# S32M24x register map
Vendor: NXP Semiconductors; File version: 1.3
CPU: CM4 r0p1, little endian, MPU, FPU, VTOR, 4 interrupt priority bits
Registers are 32-bit, read-write, reset 0x0 unless marked. A register's access mark holds for its fields unless they carry their own. Offsets are from the block's base; [hi:lo] are bit positions; {n}, {i} and the like mark numbered series; 'fields as' and 'values as' point back to an identical list.

## AEC_AE — AEC
Base 0x00000000
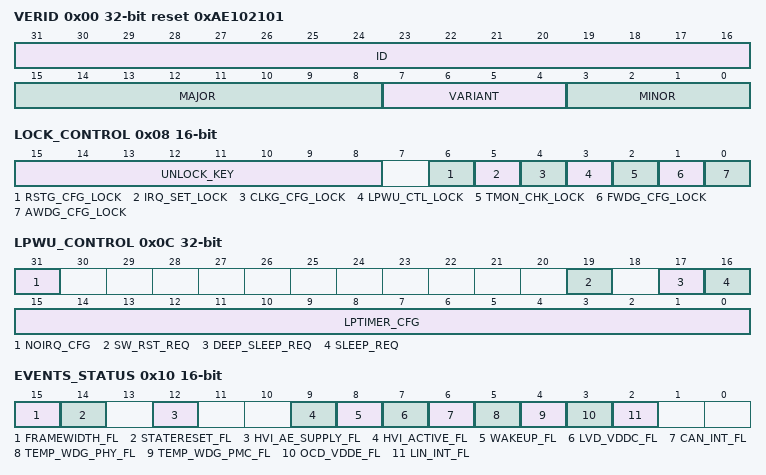
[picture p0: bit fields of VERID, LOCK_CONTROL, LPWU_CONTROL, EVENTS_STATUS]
0x00 VERID ro reset 0xAE102101 — AEC Version ID
  [31:16] ID — Unique Identifier
  [15:8] MAJOR — Major Revision
  [7:4] VARIANT
    0bxxx1=NoCXPI (CXPI is disabled)
  [3:0] MINOR — Minor Revision
0x08 LOCK_CONTROL 16-bit
  [15:8] UNLOCK_KEY
  [6] RSTG_CFG_LOCK — Lock Write Access to RSTGEN_CFG
  [5] IRQ_SET_LOCK — Lock Write Access to IRQ_SET
  [4] CLKG_CFG_LOCK — Lock Write Access to CLKGEN_CFG
  [3] LPWU_CTL_LOCK — Lock Write Access to LPWU_CONTROL
  [2] TMON_CHK_LOCK — Temperature Sensor Check Lock
  [1] FWDG_CFG_LOCK — Lock Write Access to Configuration of the FAULT Watchdog
  [0] AWDG_CFG_LOCK — Lock Write Access to Registers of the Alive Watchdog
0x0C LPWU_CONTROL — Power Mode Control
  [31] NOIRQ_CFG — No IRQ After Reset
  [19] SW_RST_REQ — Software Reset Request
  [17] DEEP_SLEEP_REQ — Deep Sleep Request
  [16] SLEEP_REQ — Sleep Request
  [15:0] LPTIMER_CFG — LP Timer Configuration
0x10 EVENTS_STATUS 16-bit — Event Notifications Status
  [15] FRAMEWIDTH_FL write-1-clears — SPI Framewidth Notification Flag
  [14] STATERESET_FL write-1-clears — State Machine Reset Notification Flag
  [12] HVI_AE_SUPPLY_FL ro — HVI1 Notification Flag
  [9] HVI_ACTIVE_FL ro — HVI0 Notification Flag
  [8] WAKEUP_FL write-1-clears — Wake-up Notification Flag
  [7] LVD_VDDC_FL ro — LVD Vddc Notification Flag
  [6] CAN_INT_FL ro — CANPHY Notification Flag
  [5] TEMP_WDG_PHY_FL ro — Temperature Monitor PHY Notification Flag
  [4] TEMP_WDG_PMC_FL ro — Temperature Monitor PMC Notification Flag
  [3] OCD_VDDE_FL write-1-clears — Over Current Detector Notification Flag
  [2] LIN_INT_FL ro — LINPHY Notification Flag
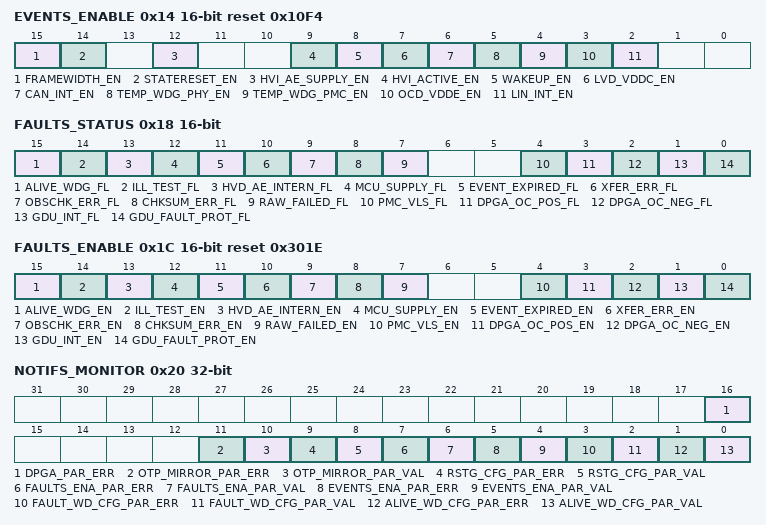
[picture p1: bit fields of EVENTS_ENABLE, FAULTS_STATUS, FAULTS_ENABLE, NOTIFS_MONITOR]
0x14 EVENTS_ENABLE 16-bit reset 0x10F4 — Event Notifications Enable
  [15] FRAMEWIDTH_EN — SPI Framewidth Notification Enable
  [14] STATERESET_EN — State Machine Reset Notification Enable
  [12] HVI_AE_SUPPLY_EN ro — HVM1 Notification Enable
  [9] HVI_ACTIVE_EN — HVM0 Notification Enable
  [8] WAKEUP_EN — Wake Up Notification Enable
  [7] LVD_VDDC_EN ro — LVD VDDC Notification Enable
  [6] CAN_INT_EN ro — CANPHY Notification Enable
  [5] TEMP_WDG_PHY_EN ro — Temperature Sensor PHY Notification Enable
  [4] TEMP_WDG_PMC_EN ro — Temperature Sensor PMC Notification Enable
  [3] OCD_VDDE_EN — Over Current Detector Notification Enable
  [2] LIN_INT_EN ro — LINPHY Notification Enable
0x18 FAULTS_STATUS 16-bit — Fault Notifications Status
  [15] ALIVE_WDG_FL write-1-clears — Alive Watchdog Flag
  [14] ILL_TEST_FL write-1-clears — Illegal Test Notification Flag
  [13] HVD_AE_INTERN_FL ro — HVD Notification Flag
  [12] MCU_SUPPLY_FL ro — MCU Supply Notification Flag
  [11] EVENT_EXPIRED_FL write-1-clears — Event Expired Notification Flag
  [10] XFER_ERR_FL write-1-clears — Transfer Error Notification Flag
  [9] OBSCHK_ERR_FL write-1-clears — OBSCHK Error Notification Flag
  [8] CHKSUM_ERR_FL write-1-clears — Checksum Error Notification Flag
  [7] RAW_FAILED_FL write-1-clears — RAW Failed Notification Flag
  [4] PMC_VLS_FL ro — PMC VLS Notification Flag
  [3] DPGA_OC_POS_FL ro — DPGA OC POS Notification Flag
  [2] DPGA_OC_NEG_FL ro — DPGA OC NEG Notification Flag
  [1] GDU_INT_FL ro — GDU Notification Flag
  [0] GDU_FAULT_PROT_FL ro — GDU Fault Protection Notification Flag
0x1C FAULTS_ENABLE 16-bit reset 0x301E — Fault Notifications Enable
  [15] ALIVE_WDG_EN — Alive Watchdog Notification Enable
  [14] ILL_TEST_EN — Illegal Test Notification Enable
  [13] HVD_AE_INTERN_EN ro — HVD Internal Notification Enable
  [12] MCU_SUPPLY_EN ro — MCU Supply Notification Enable
  [11] EVENT_EXPIRED_EN — Event Expired Notification Enable
  [10] XFER_ERR_EN — Transfer Error Notification Enable
  [9] OBSCHK_ERR_EN — OBSCHK Error Notification Enable
  [8] CHKSUM_ERR_EN — Checksum Error Notification Enable
  [7] RAW_FAILED_EN — RAW Failed Notification Enable
  [4] PMC_VLS_EN ro — PMC VLS Notification Enable
  [3] DPGA_OC_POS_EN ro — DPGA OC POS Notification Enable
  [2] DPGA_OC_NEG_EN ro — DPGA OC NEG Notification Enable
  [1] GDU_INT_EN ro — GDU Notification Enable
  [0] GDU_FAULT_PROT_EN — GDU Fault Protection Notification Enable
0x20 NOTIFS_MONITOR — Monitoring of Notifications
  [16] DPGA_PAR_ERR write-1-clears — Current Parity Value Error
  [11] OTP_MIRROR_PAR_ERR write-1-clears — Current Parity Value Error
  [10] OTP_MIRROR_PAR_VAL — Parity Value Of Mirror Registers After Completion Of Otp Boot
  [9] RSTG_CFG_PAR_ERR write-1-clears — Current Parity Value Error
  [8] RSTG_CFG_PAR_VAL — Current Parity Value
  [7] FAULTS_ENA_PAR_ERR write-1-clears — Current Parity Value Error
  [6] FAULTS_ENA_PAR_VAL — Current Parity Value
  [5] EVENTS_ENA_PAR_ERR write-1-clears — Current Parity Value Error
  [4] EVENTS_ENA_PAR_VAL — Current Parity Value
  [3] FAULT_WD_CFG_PAR_ERR write-1-clears — Current Parity Value Error
  [2] FAULT_WD_CFG_PAR_VAL — Current Parity Value
  [1] ALIVE_WD_CFG_PAR_ERR write-1-clears — Current Parity Value Error
  [0] ALIVE_WD_CFG_PAR_VAL — Current Parity Value
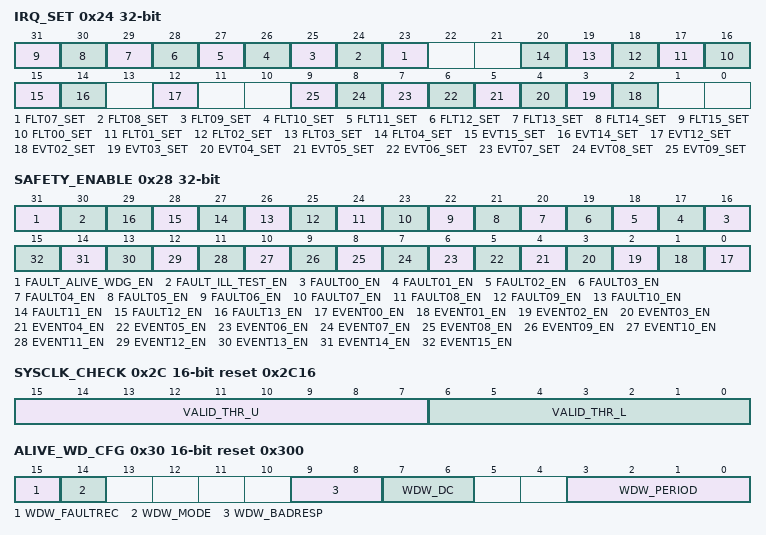
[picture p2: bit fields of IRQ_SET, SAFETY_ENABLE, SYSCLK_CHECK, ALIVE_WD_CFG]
0x24 IRQ_SET — Set Status Bits
  [n+16] FLT{n:02}_SET (n=7..15) — Forces Flag Corresponding To Fault {n}
  [n+16] FLT{n:02}_SET (n=0..4) — Forces Flag Corresponding To Fault {n}
  [15] EVT15_SET — Forces Flag Corresponding to Event 15
  [14] EVT14_SET — Forces Flag Corresponding to Event 14
  [12] EVT12_SET — Forces Flag Corresponding To Event 12
  [n] EVT{n:02}_SET (n=2..9) — Forces Flag Corresponding To Event {n}
0x28 SAFETY_ENABLE
  [31] FAULT_ALIVE_WDG_EN — Safe State Enable For FAULT ALIVE_WDG
  [30] FAULT_ILL_TEST_EN — Safe State Enable For FAULT ILL_TEST
  [n+16] FAULT{n:02}_EN ro (n=0..13) — Not Used
  [n] EVENT{n:02}_EN ro (n=0..15) — Not Used
0x2C SYSCLK_CHECK 16-bit reset 0x2C16 — System Clock Check
  [15:7] VALID_THR_U — Valid System Clock Threshold Range, Upper Boundary
  [6:0] VALID_THR_L — Valid System Clock Threshold Range, Lower Boundary
0x30 ALIVE_WD_CFG 16-bit reset 0x300 — Alive Watchdog Configuration
  [15] WDW_FAULTREC — Fault Response Configuration
    0=Unserviced watchdog triggers a fault notification (ALIVE_WDG); 1=Unserviced watchdog triggers a device reset
  [14] WDW_MODE — Watchdog Mode
    0=Simple mode. Expected response is token; 1=Challenge mode. Expected response is given by a LFSR
  [9:8] WDW_BADRESP — Max Number Of Bad Responses. Access Are Locked
    0=First incorrect response token triggers a fault event; 1=One incorrect response token permitted before triggering a fault event; 2=Two incorrect response token permitted before triggering a fault event; 3=Three incorrect response token permitted before triggering a fault event
  [7:6] WDW_DC — Window duty cycle
    0=d0 (0% Closed (feature disabled)); 1=d1 (First 31.25% closed (exact ratio: 1/2-1/4+1/16)); 2=d2 (First 50% closed); 3=d3 (First 68.75% closed (exact ratio: 1/2+1/4-1/16))
  [3:0] WDW_PERIOD — Watchdog Window Duration. Access Are Locked.
    0=d0 (Disabled); {v}=d{v} ({v}*2*512 us) (v=1..4); 5=d5 (6*2*512 us); 6=d6 (8*2*512 us); 7=d7 (23*512 us); 8=d8 (31*512 us); 9=d9 (47*512 us); 10=d10 (62*512 us); 11=d11 (125*512 us); 12=d12 (250*512 us); 13=d13 (500*512 us); 14=d14 (1000*512 us); 15=d15 (2000*512 us)
0x34 ALIVE_WD_TOKEN 16-bit reset 0x5AB2 — Alive Watchdog Reference Value
  [15:0] WD_TOKEN — Token
0x38 ALIVE_WD_ANSWER 16-bit — Alive Watchdog Answer
  [15:0] WD_ANSWER — Answer
0x3C FAULT_WD_CFG 16-bit — Fault Watchdog Configuration
  [11:0] TIME_OUT_CFG — Window Period
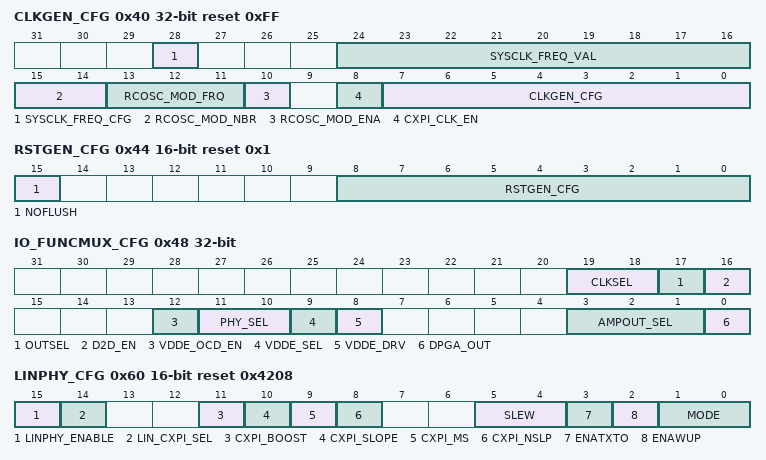
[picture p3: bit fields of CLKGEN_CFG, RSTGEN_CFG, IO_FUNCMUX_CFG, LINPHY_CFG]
0x40 CLKGEN_CFG reset 0xFF — Clock Generator Configuration
  [28] SYSCLK_FREQ_CFG — System Clock Frequency Estimator Configuration
  [24:16] SYSCLK_FREQ_VAL ro — System Clock Frequency Estimator Result
  [15:14] RCOSC_MOD_NBR — RCOSC: number of modulation used for spreading frequency.
    0=The modulation of the RCosc change between 2 frequencies; 1=The modulation of the RCosc change between 4 frequencies; 2=The modulation of the RCosc change between 8 frequencies; 3=The modulation of the RCosc change between 16 frequencies
  [13:11] RCOSC_MOD_FRQ — RCOSC: control frequency of switch for modulation
    0=modulation change at each RCosc cycle; 1=modulation change each 2 RCosc cycles; 2=modulation change each 4 RCosc cycles; 3=modulation change each 8 RCosc cycles; 4=modulation change each 16 RCosc cycles; 5=modulation change each 32 RCosc cycles; 6=modulation change each 64 RCosc cycles; 7=modulation change each 128 RCosc cycles
  [10] RCOSC_MOD_ENA — RCOSC: modulation enable
    0=DISABLE (Disable modulation on RC oscillator); 1=ENABLE (Enable modulation on RC oscillator)
  [8] CXPI_CLK_EN — Enable CXPI functional clock
  [7:0] CLKGEN_CFG — Force Enable Of Clocks
    0=Aec_sys (reg access); 1=Pmc_sys (reg access); 2=Mem_otp_sys (reg access, boot of OTP); 3=Dpga_sys (reg access; 4=Gdu_sys (reg access); 5=Hvi_sys (reg access); 6=Can_phy_apb (scheduled transfer of trimming bits from OTP); 7=Tempsensor_sys (reg access, scheduled measurement)
0x44 RSTGEN_CFG 16-bit reset 0x1 — Reset Generator Configuration
  [15] NOFLUSH — No Auto Flush
  [8:0] RSTGEN_CFG — Module Activation
    0bxxxxxxxx1=Regs_otp (resets OTP register interface, not mirror regs)
0x48 IO_FUNCMUX_CFG — IO Funcmux Configuration
  [19:18] CLKSEL — CLK_MUX_OUT: CLK Selection
    0=OSC (CLKOUT=OSC_RC 42 MHz divided by 8); 1=PMC (CLKOUT=PMC FRO 150kHz); 2=CANWU8 (CLKOUT=CANPHY clkwuosc divided by 8); 3=CANTRX256 (CLKOUT=CANPHY clkosctrx divided by 256)
  [17] OUTSEL — CLK_MUX_OUT: OUT Selection
    0=CLK (CLKOUT); 1=LINPHY (LIN Checking (LINPHY_RX))
  [16] D2D_EN — CLK_MUX_OUT: D2D Enable
    0=DISABLE (CLK_MUX_OUT Is in tristate); 1=ENABLE (CLK_MUX_OUT Pad is enabled)
  [12] VDDE_OCD_EN — Enable Over Current Detection
    0=DISABLE (VDDE Overcurrent detector is disabled); 1=ENABLE (VDDE Overcurrent detector is enabled)
  [11:10] PHY_SEL — VDDE PHY Selection
    0=NOTUSED0 (VDDE Input not used and not driven); 1=NOTUSED1 (VDDE Input not used and not driven); 2=CANPHY (VDDE Use as input for CANPHY_Tx); 3=LINPHY (VDDE Use as input for LINPHY_Tx)
  [9] VDDE_SEL — VDDE Selection
    0=DISABLE (Weak GND); 1=ENABLE (Strong VDD)
  [8] VDDE_DRV — VDDE Driver
    0=DIGITAL (Digital mode, VDDE as input depends of PHY_SEL); 1=ANALOG (Analog mode, VDDE as output depends of VDDE_SEL)
  [3:1] AMPOUT_SEL — AMPOUT_cjtag1: AMPOUT Selection
    0=DPGA (Hi-Z (analog AMPOUT)); 1=CANPHY (CANPHY_RX); 2=LINPHY (LINPHY_RX); 3=CANPHYWURX; 4=OSC (Oscillator out (see CLKOUT)); 5=PWM0; 6=PWM2; 7=PWM4
  [0] DPGA_OUT — AMPOUT_cjtag1: DPGA out Selection
    0=DIGITAL (Digital mode, AMPOUT depends of AMPOUT_SEL); 1=ANALOG (Analog mode, dpga is connected to ampout through an anamux)
0x60 LINPHY_CFG 16-bit reset 0x4208 — LINPHY Configuration
  [15] LINPHY_ENABLE
  [14] LIN_CXPI_SEL — Select protocol used on LIN line.
    0=LIN (Select LIN protocol); 1=CXPI (Select CXPI protocol)
  [11] CXPI_BOOST — Configures control of the falling edge.
    0=ENABLE (Fast falling edge behavior enabled.); 1=DISABLE (Fast falling edge behavior disabled)
  [10] CXPI_SLOPE — Configures controlled slope timings
    0=LIN (Slope is optimized for LIN operation.); 1=CXPI (Slope is optimized for CXPI operation.)
  [9] CXPI_MS — CXPI Slave/Master mode.
    0=MASTER (Device is configured in CXPI master mode.); 1=SLAVE (Device is configured in CXPI slave mode.)
  [8] CXPI_NSLP — CXPI No Sleep
    0=SLEEP (CXPI is in sleep mode.); 1=NORMAL (CXPI is in normal mode.)
  [5:4] SLEW — Configures The Slew Rate Of LINPHY
    0=Slew rate optimized for Baud-Rate of 20kBIt/s; 1=Slew rate optimized for Baud-Rate of 115kbits (not LIN compliant); 2=Slew rate optimized for Baud-Rate of 10.4kBIt/s
  [3] ENATXTO — Configures the TX Dominant Timeout Detection Of LINPHY
    0=TX dominant timeout detection disabled; 1=TX dominant timeout detection enabled
  [2] ENAWUP — Configures The Wakeup Receiver Of LINPHYs
    0=Wakeup receiver disabled; 1=Wakeup receiver enabled
  [1:0] MODE — Configures The Operating Mode Of LINPHY
    0=OFForWakeCapable (Off when ENAWUP=0 or Wake capable when ENAWUP=1); 1=ListenOnly; 2=Active (Normal)
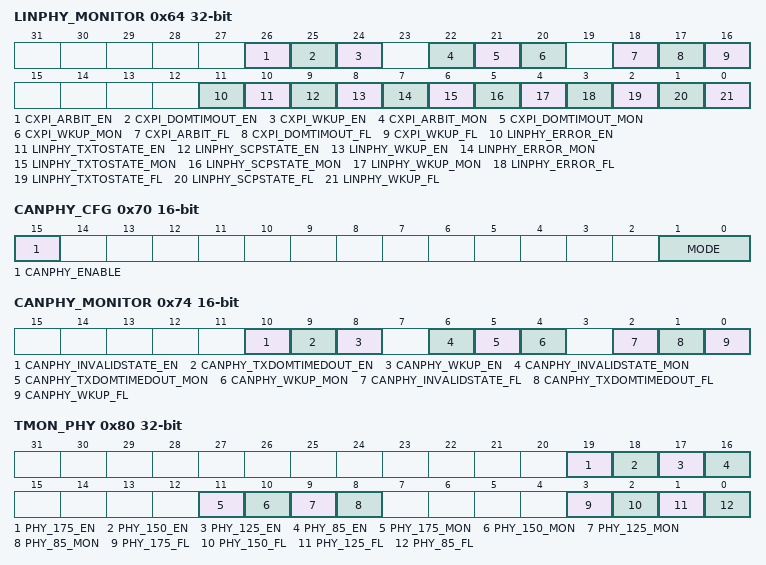
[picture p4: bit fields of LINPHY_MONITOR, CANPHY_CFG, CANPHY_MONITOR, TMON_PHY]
0x64 LINPHY_MONITOR
  [26] CXPI_ARBIT_EN — CXPI arbitration lost interrupt enable
    0=CXPI arbitration lost interrupt disabled; 1=CXPI_ARBIT_FL causeas an interrupt
  [25] CXPI_DOMTIMOUT_EN — CXPI dominant timout Interrupt Enable
    0=CXPI dominant timout Interrupt Disable; 1=CXPI_DOMTIMOUT_FL causes an interrupt
  [24] CXPI_WKUP_EN — CXPI Wakeup Interrupt Enable
    0=CXPI wakeup interrupt disabled; 1=CXPI_WKUP_FL causes an interrupt
  [22] CXPI_ARBIT_MON ro — Status of CXPI arbitration lost
    0=CXPI arbitration is not lost; 1=CXPI arbitration is lost
  [21] CXPI_DOMTIMOUT_MON ro — Status of the CXPI TX Timeout Detector
    0=CXPI dominant timout inactive; 1=CXPI dominant timout active
  [20] CXPI_WKUP_MON ro — Status Of The CXPI Wakeup Detector
    0=CXPI wakeup inactive; 1=CXPI wakeup active
  [18] CXPI_ARBIT_FL write-1-clears — CXPI arbitration lost
    0=No CXPI arbitration lost event detected; 1=CXPI arbitration lost event detected
  [17] CXPI_DOMTIMOUT_FL write-1-clears — CXPI TX Timeout Detector
    0=No CXPI TX dominant timeout event detected; 1=CXPI TX dominant timeout event detected
  [16] CXPI_WKUP_FL write-1-clears — CXPI Wakeup
    0=No CXPI wakeup event detected; 1=CXPI wakeup event detected
  [11] LINPHY_ERROR_EN — LIN FSM Error Interrupt Enable
    0=Linphy FSM error interrupt disabled; 1=LINPHY_ERROR_FL causes an interrupt
  [10] LINPHY_TXTOSTATE_EN — LIN TX dominant Timeout Interrupt Enable
    0=Linphy dominant timeout interrupt disabled; 1=LINPHY_TXTOSTATE_FL causes an interrupt
  [9] LINPHY_SCPSTATE_EN — LIN Short Circuit Interrupt Enable
    0=Linphy short circuit interrupt disabled; 1=LINPHY_SCPSTATE_FL causes an interrupt
  [8] LINPHY_WKUP_EN — LIN Wakeup Interrupt Enable
    0=Linphy wakeup interrupt disabled; 1=LINPHY_WKUP_FL causes an interrupt
  [7] LINPHY_ERROR_MON ro — Status Of The LIN FSM Error
    0=Error in LIN FSM inactive; 1=Error in LIN FSM active
  [6] LINPHY_TXTOSTATE_MON ro — Status Of The LIN TX Dominant Timeout Detector
    0=LIN TX dominant timeout protection inactive; 1=LIN TX dominant timeout protection active
  [5] LINPHY_SCPSTATE_MON ro — Status Of The LIN Short Circuit Detector
    0=LIN short circuit protection inactive; 1=LIN short circuit protection active
  [4] LINPHY_WKUP_MON ro — Status Of The LIN Wakeup Detector
    0=LIN wakeup inactive; 1=LIN wakeup active
  [3] LINPHY_ERROR_FL write-1-clears — LIN FSM Error
    0=No error in LIN FSM detected; 1=Error in LIN FSM detected
  [2] LINPHY_TXTOSTATE_FL write-1-clears — LIN TX Timeout Detector
    0=No LIN TX dominant timeout event detected; 1=LIN TX dominant timeout event detected
  [1] LINPHY_SCPSTATE_FL write-1-clears — LIN Short Circuit
    0=No LIN short circuit event detected; 1=LIN short circuit event detected
  [0] LINPHY_WKUP_FL write-1-clears — LIN Wakeup
    0=No LIN wakeup event detected; 1=LIN wakeup event detected
0x70 CANPHY_CFG 16-bit — CANPHY Configuration
  [15] CANPHY_ENABLE
  [1:0] MODE — CANPHY Mode Control
    0=Offline mode; 1=Normal mode; 3=Listen only mode
0x74 CANPHY_MONITOR 16-bit
  [10] CANPHY_INVALIDSTATE_EN — CANPHY FSM Error Notification Enable
    0=DISABLE (CANPHY FSM error notification disabled); 1=ENABLE (CANPHY_INVALIDSTATE_FL triggers a notification)
  [9] CANPHY_TXDOMTIMEDOUT_EN — CANPHY TX Dominant Timeout Notification Enable
    0=DISABLE (CANPHY TX dominant timeout notification disabled); 1=ENABLE (CANPHY_TXDOMTIMEDOUT_FL triggers a notification)
  [8] CANPHY_WKUP_EN — CANPHY Wakeup Notification Enable
    0=DISABLE (CANPHY wakeup notification disabled); 1=ENABLE (CANPHY_WKUP_FL triggers a notification)
  [6] CANPHY_INVALIDSTATE_MON ro — Live Status Of The CANPHY FSM Error
    0=DISABLE (No error in CANPHY FSM); 1=ENABLE (Error in CANPHY FSM)
  [5] CANPHY_TXDOMTIMEDOUT_MON ro — Live status of the CANPHY TX dominant timeout detector
    0=DISABLE (CANPHY TX dominant timeout protection inactive); 1=ENABLE (CANPHY TX dominant timeout protection active)
  [4] CANPHY_WKUP_MON ro — Live Status Of The CANPHY Wakeup Detector
    0=DISABLE (CANPHY wakeup inactive); 1=ENABLE (CANPHY wakeup active)
  [2] CANPHY_INVALIDSTATE_FL write-1-clears — CANPHY Invalid State
    0=DISABLE (No CANPHY FSM error event detected); 1=ENABLE (CANPHY FSM error event detected)
  [1] CANPHY_TXDOMTIMEDOUT_FL write-1-clears — CANPHY TX Dominant Timeout
    0=DISABLE (No CANPHY TX dominant timeout event detected); 1=ENABLE (CANPHY TX dominant timeout event detected)
  [0] CANPHY_WKUP_FL write-1-clears — CANPHY Wakeup
    0=DISABLE (No CANPHY wakeup event detected); 1=ENABLE (CANPHY wakeup event detected)
0x80 TMON_PHY — Temperature Monitor PHY
  [19] PHY_175_EN — PHY 175degree Enable
    0=DISABLE (Disable generation of a notification event); 1=ENABLE (Enable generation of a notification event)
  [18] PHY_150_EN — PHY 150degree Enable
    values as PHY_175_EN
  [17] PHY_125_EN — PHY 125degree Enable
    values as PHY_175_EN
  [16] PHY_85_EN — PHY 85degree Enable
    values as PHY_175_EN
  [11] PHY_175_MON ro — PHY Temperature Sensor Is Over 175degree C
  [10] PHY_150_MON ro — PHY Temperature Sensor Is Over 150degree C
  [9] PHY_125_MON ro — PHY Temperature Sensor Is Over 125degree C
  [8] PHY_85_MON ro — PHY Temperature Sensor Is Over 85degree C
  [3] PHY_175_FL write-1-clears — Status flag for temperature crossing over 175degree C This is a sticky-bit implemented as W1C that is set whenever this temperature is reached
  [2] PHY_150_FL write-1-clears — PHY 150degree Flag
  [1] PHY_125_FL write-1-clears — PHY 125degree Flag
  [0] PHY_85_FL write-1-clears — PHY 85degree Flag
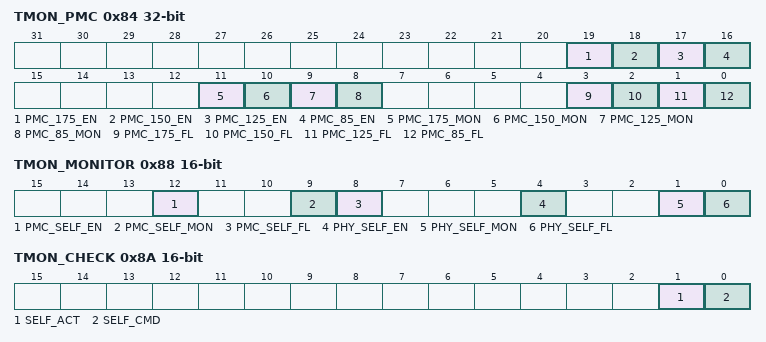
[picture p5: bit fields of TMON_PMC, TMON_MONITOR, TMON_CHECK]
0x84 TMON_PMC — Temperature Monitor PMC
  [19] PMC_175_EN — PMC 175degree Enable
    values as TMON_PHY.PHY_175_EN
  [18] PMC_150_EN — PMC 150degree Enable
    values as TMON_PHY.PHY_175_EN
  [17] PMC_125_EN — PMC 125degree Enable
    values as TMON_PHY.PHY_175_EN
  [16] PMC_85_EN — PMC 85degree Enable
    values as TMON_PHY.PHY_175_EN
  [11] PMC_175_MON ro — PMC Temperature Sensor Is Over 175degree C
  [10] PMC_150_MON ro — PMC Temperature Sensor Is Over 150degree C
  [9] PMC_125_MON ro — PMC Temperature Sensor Is Over 125degree C
  [8] PMC_85_MON ro — PMC Temperature Sensor Is Over 85degree C
  [3] PMC_175_FL write-1-clears — PMC 175degree Flag
  [2] PMC_150_FL write-1-clears — PMC 150degree Flag
  [1] PMC_125_FL write-1-clears — PMC 125degree Flag
  [0] PMC_85_FL write-1-clears — PMC 85degree Flag
0x88 TMON_MONITOR 16-bit
  [12] PMC_SELF_EN — TEMPSENSOR PMC self-test Failure Enable
  [9] PMC_SELF_MON ro — TEMPSENSOR Monitor Self-test
  [8] PMC_SELF_FL write-1-clears — TEMPSENSOR PMC Self-test Failure Status
  [4] PHY_SELF_EN — TEMPSENSOR PHY Self-test Failure Enable
  [1] PHY_SELF_MON ro — TEMPSENSOR Monitor Self-Test
  [0] PHY_SELF_FL write-1-clears — TEMPSENSOR PHY Self-test Failure Status
0x8A TMON_CHECK 16-bit
  [1] SELF_ACT ro — Status Of Self-check Command
    0=Self-check is inactive; 1=Self-check is active, still running
  [0] SELF_CMD — Trigger self-test On Both Temp Sensors
    1=Trigger a new self-test
